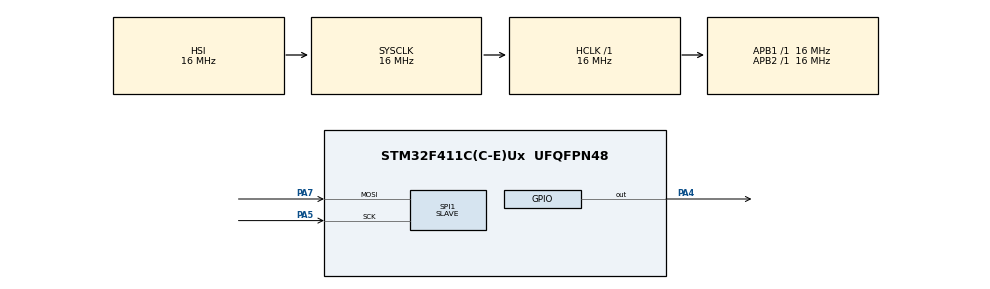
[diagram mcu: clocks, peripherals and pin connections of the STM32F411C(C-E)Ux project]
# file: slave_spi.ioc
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Mcu.Family=STM32F4
Mcu.Name=STM32F411C(C-E)Ux
Mcu.Package=UFQFPN48
NVIC.PriorityGroup=NVIC_PRIORITYGROUP_4
PA13.Mode=Trace_Asynchronous_SW
PA13.Signal=SYS_JTMS-SWDIO
PA14.Mode=Trace_Asynchronous_SW
PA14.Signal=SYS_JTCK-SWCLK
PA4.PinState=GPIO_PIN_SET
PA4.Signal=GPIO_Output
PA5.Mode=RX_Only_Simplex_Unidirect_Slave
PA5.Signal=SPI1_SCK
PA7.Mode=RX_Only_Simplex_Unidirect_Slave
PA7.Signal=SPI1_MOSI
PB3.Mode=Trace_Asynchronous_SW
PB3.Signal=SYS_JTDO-SWO
ProjectManager.HeapSize=0x200
ProjectManager.StackSize=0x400
ProjectManager.TargetToolchain=STM32CubeIDE
RCC.AHBFreq_Value=16000000
RCC.APB1Freq_Value=16000000
RCC.APB2Freq_Value=16000000
RCC.CortexFreq_Value=16000000
RCC.HSE_VALUE=25000000
RCC.HSI_VALUE=16000000
RCC.LSE_VALUE=32768
RCC.SYSCLKFreq_VALUE=16000000
RCC.VCOOutputFreq_Value=192000000
SPI1.Direction=SPI_DIRECTION_2LINES_RXONLY
SPI1.Mode=SPI_MODE_SLAVE
SPI1.VirtualType=VM_SLAVE
board=custom

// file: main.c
/* USER CODE BEGIN Header */
/**
  ******************************************************************************
  * @file           : main.c
  * @brief          : Main program body
  ******************************************************************************
  * @attention
  *
  * Copyright (c) 2023 STMicroelectronics.
  * All rights reserved.
  *
  * This software is licensed under terms that can be found in the LICENSE file
  * in the root directory of this software component.
  * If no LICENSE file comes with this software, it is provided AS-IS.
  *
  ******************************************************************************
  */
/* USER CODE END Header */
#include "main.h"
#include <stdio.h>

/* USER CODE BEGIN PD */
char receivedData[5] = {0};

/* USER CODE END PD */

SPI_HandleTypeDef hspi1;

void SystemClock_Config(void);
static void MX_GPIO_Init(void);
static void MX_SPI1_Init(void);

/* USER CODE BEGIN 0 */
int _write(int file, char *ptr, int len)
{
	int i=0;
	for(i=0 ; i<len ; i++)
	  ITM_SendChar((*ptr++));
	return len;
}

/* USER CODE END 0 */

int main(void)
{

  /* MCU Configuration--------------------------------------------------------*/

  /* Reset of all peripherals, Initializes the Flash interface and the Systick. */
  HAL_Init();

  /* Configure the system clock */
  SystemClock_Config();

  /* Initialize all configured peripherals */
  MX_GPIO_Init();
  MX_SPI1_Init();

  /* Infinite loop */
  /* USER CODE BEGIN WHILE */
  while (1)
  {

	  HAL_SPI_Receive(&hspi1, (uint8_t *)receivedData, sizeof(receivedData), HAL_MAX_DELAY);

	  for (int i = 0; i < sizeof(receivedData); i++)
	  {
		  printf("Received data[%d]: %c\n", i, receivedData[i]);
	  }

    /* USER CODE END WHILE */

  }
}

void SystemClock_Config(void)
{
  RCC_OscInitTypeDef RCC_OscInitStruct = {0};
  RCC_ClkInitTypeDef RCC_ClkInitStruct = {0};

  /** Configure the main internal regulator output voltage
  */
  __HAL_RCC_PWR_CLK_ENABLE();
  __HAL_PWR_VOLTAGESCALING_CONFIG(PWR_REGULATOR_VOLTAGE_SCALE1);

  /** Initializes the RCC Oscillators according to the specified parameters
  * in the RCC_OscInitTypeDef structure.
  */
  RCC_OscInitStruct.OscillatorType = RCC_OSCILLATORTYPE_HSI;
  RCC_OscInitStruct.HSIState = RCC_HSI_ON;
  RCC_OscInitStruct.HSICalibrationValue = RCC_HSICALIBRATION_DEFAULT;
  RCC_OscInitStruct.PLL.PLLState = RCC_PLL_NONE;
  if (HAL_RCC_OscConfig(&RCC_OscInitStruct) != HAL_OK)
  {
    Error_Handler();
  }

  /** Initializes the CPU, AHB and APB buses clocks
  */
  RCC_ClkInitStruct.ClockType = RCC_CLOCKTYPE_HCLK|RCC_CLOCKTYPE_SYSCLK
                              |RCC_CLOCKTYPE_PCLK1|RCC_CLOCKTYPE_PCLK2;
  RCC_ClkInitStruct.SYSCLKSource = RCC_SYSCLKSOURCE_HSI;
  RCC_ClkInitStruct.AHBCLKDivider = RCC_SYSCLK_DIV1;
  RCC_ClkInitStruct.APB1CLKDivider = RCC_HCLK_DIV1;
  RCC_ClkInitStruct.APB2CLKDivider = RCC_HCLK_DIV1;

  if (HAL_RCC_ClockConfig(&RCC_ClkInitStruct, FLASH_LATENCY_0) != HAL_OK)
  {
    Error_Handler();
  }
}

static void MX_SPI1_Init(void)
{

  /* SPI1 parameter configuration*/
  hspi1.Instance = SPI1;
  hspi1.Init.Mode = SPI_MODE_SLAVE;
  hspi1.Init.Direction = SPI_DIRECTION_2LINES_RXONLY;
  hspi1.Init.DataSize = SPI_DATASIZE_8BIT;
  hspi1.Init.CLKPolarity = SPI_POLARITY_LOW;
  hspi1.Init.CLKPhase = SPI_PHASE_1EDGE;
  hspi1.Init.NSS = SPI_NSS_SOFT;
  hspi1.Init.FirstBit = SPI_FIRSTBIT_MSB;
  hspi1.Init.TIMode = SPI_TIMODE_DISABLE;
  hspi1.Init.CRCCalculation = SPI_CRCCALCULATION_DISABLE;
  hspi1.Init.CRCPolynomial = 10;
  if (HAL_SPI_Init(&hspi1) != HAL_OK)
  {
    Error_Handler();
  }

}

static void MX_GPIO_Init(void)
{
  GPIO_InitTypeDef GPIO_InitStruct = {0};

  /* GPIO Ports Clock Enable */
  __HAL_RCC_GPIOA_CLK_ENABLE();
  __HAL_RCC_GPIOB_CLK_ENABLE();

  /*Configure GPIO pin Output Level */
  HAL_GPIO_WritePin(GPIOA, GPIO_PIN_4, GPIO_PIN_SET);

  /*Configure GPIO pin : PA4 */
  GPIO_InitStruct.Pin = GPIO_PIN_4;
  GPIO_InitStruct.Mode = GPIO_MODE_OUTPUT_PP;
  GPIO_InitStruct.Pull = GPIO_NOPULL;
  GPIO_InitStruct.Speed = GPIO_SPEED_FREQ_LOW;
  HAL_GPIO_Init(GPIOA, &GPIO_InitStruct);

}

void Error_Handler(void)
{
  __disable_irq();
  while (1)
  {
  }
}
